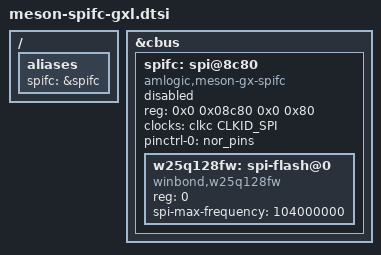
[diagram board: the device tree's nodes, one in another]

&cbus {
    spifc: spi@8c80 {
	compatible = "amlogic,meson-gx-spifc", "amlogic,meson-gxbb-spifc";
	reg = <0x0 0x08c80 0x0 0x80>;
	#address-cells = <1>;
	#size-cells = <0>;
	clocks = <&clkc CLKID_SPI>;
	status = "disabled";
    };
};


&spifc {
//  status = "okay";
    status = "disabled";
    pinctrl-0 = <&nor_pins>;
    pinctrl-names = "default";

    w25q128fw: spi-flash@0 {
    #address-cells = <1>;
    #size-cells = <1>;
    compatible = "winbond,w25q128fw", "jedec,spi-nor";
    reg = <0>;
    spi-max-frequency = <104000000>;
    };
};

/ {
    aliases {
    spifc = &spifc;
    };
};

